# ATmega406 device description
Architecture: AVR8; Family: megaAVR
Programming and debug interfaces: HVPP, JTAG
Registers are 8-bit, access not given, no defined reset value unless marked. A register's access mark holds for its fields unless they carry their own. Offsets are from the block's base; lines under a group give offsets from that group; [hi:lo] are bit positions; {n}, {i} and the like mark numbered series; 'fields as' and 'values as' point back to an identical list; <NAME> marks a mode.

## Ordering variants
standard: 4.0 to 5.5 V

## Memory
prog space: start 0x0000 size 0xa000, little endian
  0x0000 FLASH size 0xa000 flash, rw, executable, page 0x80
  0x9e00 BOOT_SECTION_1 size 0x0200 flash, rw, executable, page 0x80
  0x9c00 BOOT_SECTION_2 size 0x0400 flash, rw, executable, page 0x80
  0x9800 BOOT_SECTION_3 size 0x0800 flash, rw, executable, page 0x80
  0x9000 BOOT_SECTION_4 size 0x1000 flash, rw, executable, page 0x80
signatures space: start 0 size 3, little endian
  0 SIGNATURES size 3 signatures, ro
fuses space: start 0 size 0x0002, little endian
  0 FUSES size 0x0002 fuses, rw
lockbits space: start 0 size 0x0001, little endian
  0 LOCKBITS size 0x0001 lockbits, rw
data space: start 0x0000 size 0x0900, little endian
  0x0000 REGISTERS size 0x0020 regs
  0x0020 MAPPED_IO size 0x00e0 io
  0x0100 IRAM size 0x0800 ram
eeprom space: start 0x0000 size 0x0200, little endian
  0x0000 EEPROM size 0x0200 eeprom, rw, page 0x04
io space: start 0x00 size 0x40, little endian

## Peripheral instances (address, pins/pin function, parameters)
ADC at 0x00 — Analog-to-Digital Converter
EXINT at 0x00 — External Interrupts
TC1 at 0x00 — Timer/Counter, 16-bit
WAKEUP_TIMER at 0x00
BATTERY_PROTECTION at 0x00
FET at 0x00 — FET Control
COULOMB_COUNTER at 0x00
CELL_BALANCING at 0x00
CPU at 0x00 — CPU Registers
  parameters: CORE_VERSION=V2E
WDT at 0x00 — Watchdog Timer
TC0 at 0x00 — Timer/Counter, 8-bit
PORTA at 0x00 — I/O Port
PORTB at 0x00 — I/O Port
PORTC at 0x00 — I/O Port
PORTD at 0x00 — I/O Port
BOOT_LOAD at 0x00 — Bootloader
TWI at 0x00 — Two Wire Serial Interface
BANDGAP at 0x00
EEPROM at 0x00
FUSE at 0 in fuses — Fuses
LOCKBIT at 0 in lockbits — Lockbits

## Interrupts
0 RESET — External Pin, Power-on Reset, Brown-out Reset and Watchdog Reset
1 BPINT — Battery Protection Interrupt
2 INT0 — External Interrupt Request 0
3 INT1 — External Interrupt Request 1
4 INT2 — External Interrupt Request 2
5 INT3 — External Interrupt Request 3
6 PCINT0 — Pin Change Interrupt 0
7 PCINT1 — Pin Change Interrupt 1
8 WDT — Watchdog Timeout Interrupt
9 WAKE_UP — Wakeup timer overflow
10 TIM1_COMP — Timer/Counter 1 Compare Match
11 TIM1_OVF — Timer/Counter 1 Overflow
12 TIM0_COMPA — Timer/Counter0 Compare A Match
13 TIM0_COMPB — Timer/Counter0 Compare B Match
14 TIM0_OVF — Timer/Counter0 Overflow
15 TWI_BUS_CD — Two-Wire Bus Connect/Disconnect
16 TWI — Two-Wire Serial Interface
17 VADC — Voltage ADC Conversion Complete
18 CCADC_CONV — Coulomb Counter ADC Conversion Complete
19 CCADC_REG_CUR — Coloumb Counter ADC Regular Current
20 CCADC_ACC — Coloumb Counter ADC Accumulator
21 EE_READY — EEPROM Ready
22 SPM_READY — Store Program Memory Ready

## Properties
SIGNATURES: JTAGID=0x0950703F, SIGNATURE0=0x1e, SIGNATURE1=0x95, SIGNATURE2=0x07
OCD: OCD_REVISION=3, OCD_DATAREG=0x31, PROGBASE=0x0000

## FUSE — Fuses
Instances: FUSE 0 in fuses
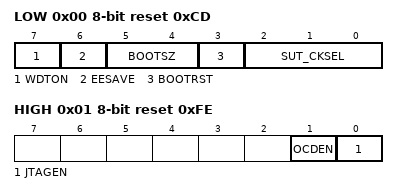
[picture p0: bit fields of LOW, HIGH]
0x00 LOW reset 0xCD
  [7] WDTON — Watchdog timer always on
  [6] EESAVE — Preserve EEPROM through the Chip Erase cycle
  [5:4] BOOTSZ — Select boot size
    3=256W_4F00 (Boot Flash size=256 words Boot address=$4F00); 2=512W_4E00 (Boot Flash size=512 words Boot address=$4E00); 1=1024W_4C00 (Boot Flash size=1024 words Boot address=$4C00); 0=2048W_4800 (Boot Flash size=2048 words Boot address=$4800)
  [3] BOOTRST — Boot Reset vector Enabled
  [2:0] SUT_CKSEL — Clock Selection
    0=14CK_0MS (Start-up time: 14 CK + 0 ms); 2=14CK_3MS9 (Start-up time: 14 CK + 3.9 ms); 4=14CK_62MS5 (Start-up time: 14 CK + 62.5 ms); 1=14CK_0MS (Start-up time: 14 CK + 0 ms); 3=14CK_3MS9 (Start-up time: 14 CK + 3.9 ms); 5=14CK_62MS5 (Start-up time: 14 CK + 62.5 ms)
0x01 HIGH reset 0xFE
  [1] OCDEN — On-Chip Debug Enabled
  [0] JTAGEN — JTAG Interface Enabled
